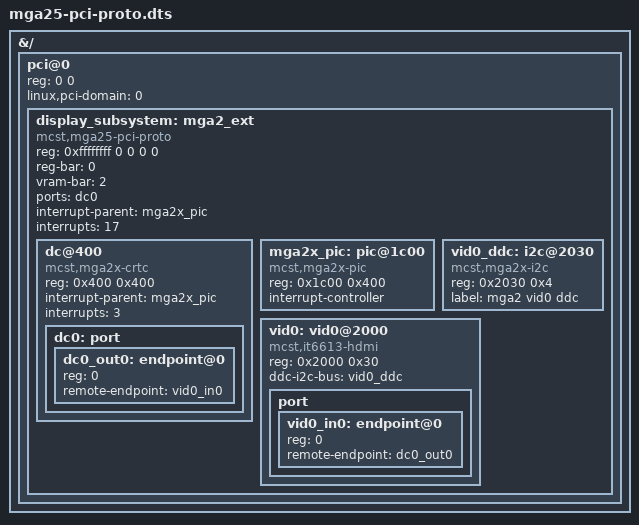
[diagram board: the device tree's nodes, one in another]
/*
 * SPDX-License-Identifier: GPL-2.0
 * Copyright (c) 2023 MCST
 */

/dts-v1/;
/plugin/;

&{/} {
	#address-cells = <1>;
	#size-cells = <1>;

	pci@0 {
		reg = <0 0>;
		linux,pci-domain = <0>;
		/* 1:1 translation, max size (48-bit) of e2k address space */
		ranges = <0 0 0 0 0x10000 0>;
		#address-cells = <3>;
		#size-cells = <2>;
		/* reg: DDDDDDDD bbbbbbbb dddddfff 00000000 */
		display_subsystem: mga2_ext {
			reg = <0xffffffff 0 0 0 0>;
			compatible = "mcst,mga25-pci-proto", "mcst,mga26-pci-proto";
		};
	};
};

#define VID0_STS "okay"

&display_subsystem {
	reg-bar = <0>;
	vram-bar = <2>;
	ports = <&dc0>;

	interrupt-parent = <&mga2x_pic>;
	interrupts = <17>;

	#address-cells = <1>;
	#size-cells = <1>;

	dc@400 {
		compatible = "mcst,mga2x-crtc";
		reg = <0x400 0x400>;

		interrupt-parent = <&mga2x_pic>;
		interrupts = <3>;

		dc0: port {
			#address-cells = <1>;
			#size-cells = <0>;

			dc0_out0: endpoint@0 {
				reg = <0>;
				remote-endpoint = <&vid0_in0>;
			};
		};
	};

	mga2x_pic: pic@1c00 {
		compatible = "mcst,mga2x-pic";
		reg = <0x1c00 0x400>;
		interrupt-controller;
		#interrupt-cells = <1>;
	};

	vid0_ddc: i2c@2030 {
		reg = <0x2030 0x4>;
		status = VID0_STS;
	};
	vid0: vid0@2000 {
		reg = <0x2000 0x30>;
		status = VID0_STS;
	};
};

&vid0 {
	compatible = "mcst,it6613-hdmi";
	ddc-i2c-bus = <&vid0_ddc>;

	port {
		#address-cells = <1>;
		#size-cells = <0>;
		vid0_in0: endpoint@0 {
			reg = <0>;
			remote-endpoint = <&dc0_out0>;
		};
	};
};

&vid0_ddc {
	compatible = "mcst,mga2x-i2c";
	label = "mga2 vid0 ddc";
};
